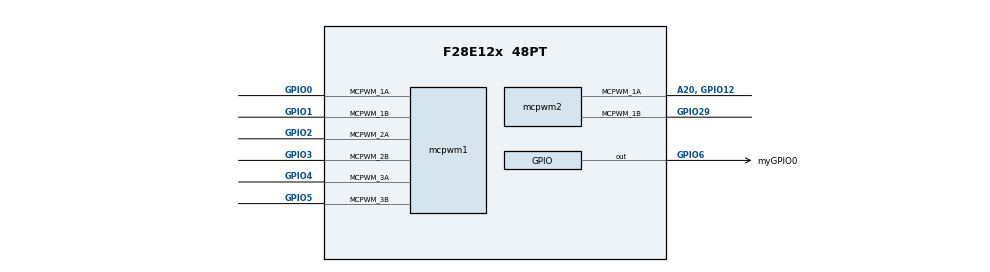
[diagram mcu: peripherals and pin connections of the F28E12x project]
/**
 * @cliArgs --device "F28E12x" --package "48PT" --part "F28E12x_48PT" --context "system" --product "C2000WARE@5.04.00.00"
 * @versions {"tool":"1.21.0+dev"}
 */

/**
 * Import the modules used in this configuration.
 */
const gpio             = scripting.addModule("/driverlib/gpio.js", {}, false);
const gpio1            = gpio.addInstance();
const inputxbar_input  = scripting.addModule("/driverlib/inputxbar_input.js", {}, false);
const inputxbar_input1 = inputxbar_input.addInstance();
const mcpwm            = scripting.addModule("/driverlib/mcpwm.js");
const mcpwm1           = mcpwm.addInstance();
const mcpwm2           = mcpwm.addInstance();
const pwmxbar          = scripting.addModule("/driverlib/pwmxbar.js", {}, false);
const pwmxbar1         = pwmxbar.addInstance();

/**
 * Write custom configuration values to the imported modules.
 */
gpio1.$name           = "myGPIO0";
gpio1.direction       = "GPIO_DIR_MODE_OUT";
gpio1.gpioPin.$assign = "GPIO6";

inputxbar_input1.$name          = "myINPUTXBARINPUT0";
inputxbar_input1.inputxbarInput = "XBAR_INPUT13";
inputxbar_input1.inputxbarGpio  = "GPIO6";

mcpwm.commentOutDefaultCode = true;

mcpwm1.$name                                                       = "myMCPWM0";
mcpwm1.mcpwmTimebase_counterMode                                   = "MCPWM_COUNTER_MODE_UP";
mcpwm1.mcpwmTimebase_period                                        = 15999;
mcpwm1.mcpwmCounterCompare_cmpA                                    = 7999;
mcpwm1.mcpwmCounterCompare_cmpB                                    = 7999;
mcpwm1.mcpwmActionQualifier_MCPWM_AQ_OUTPUT_1A_ON_TIMEBASE_ZERO    = "MCPWM_AQ_OUTPUT_HIGH";
mcpwm1.mcpwmActionQualifier_MCPWM_AQ_OUTPUT_1B_ON_TIMEBASE_ZERO    = "MCPWM_AQ_OUTPUT_HIGH";
mcpwm1.mcpwmActionQualifier_MCPWM_AQ_OUTPUT_1A_ON_TIMEBASE_UP_CMPA = "MCPWM_AQ_OUTPUT_LOW";
mcpwm1.mcpwmActionQualifier_MCPWM_AQ_OUTPUT_1B_ON_TIMEBASE_UP_CMPB = "MCPWM_AQ_OUTPUT_LOW";
mcpwm1.mcpwmActionQualifier_MCPWM_AQ_OUTPUT_2A_ON_TIMEBASE_PERIOD  = "MCPWM_AQ_OUTPUT_LOW";
mcpwm1.mcpwmActionQualifier_MCPWM_AQ_OUTPUT_2B_ON_TIMEBASE_PERIOD  = "MCPWM_AQ_OUTPUT_LOW";
mcpwm1.mcpwmActionQualifier_MCPWM_AQ_OUTPUT_2A_ON_TIMEBASE_UP_CMPA = "MCPWM_AQ_OUTPUT_HIGH";
mcpwm1.mcpwmActionQualifier_MCPWM_AQ_OUTPUT_2B_ON_TIMEBASE_UP_CMPB = "MCPWM_AQ_OUTPUT_HIGH";
mcpwm1.mcpwmActionQualifier_MCPWM_AQ_OUTPUT_3A_ON_TIMEBASE_UP_CMPA = "MCPWM_AQ_OUTPUT_HIGH";
mcpwm1.mcpwmActionQualifier_MCPWM_AQ_OUTPUT_3A_ON_TIMEBASE_UP_CMPB = "MCPWM_AQ_OUTPUT_LOW";
mcpwm1.mcpwmActionQualifier_MCPWM_AQ_OUTPUT_3B_ON_TIMEBASE_UP_CMPA = "MCPWM_AQ_OUTPUT_LOW";
mcpwm1.mcpwmActionQualifier_MCPWM_AQ_OUTPUT_3B_ON_TIMEBASE_UP_CMPB = "MCPWM_AQ_OUTPUT_HIGH";
mcpwm1.mcpwmEventTrigger_enableInterrupt                           = true;
mcpwm1.mcpwmEventTrigger_registerInterrupts                        = true;
mcpwm1.mcpwmCounterCompare_cmpA_pwm2                               = 7999;
mcpwm1.mcpwmCounterCompare_cmpB_pwm2                               = 7999;
mcpwm1.mcpwmCounterCompare_cmpB_pwm3                               = 7999;
mcpwm1.mcpwmEventTrigger_interruptSource                           = ["MCPWM_INT_TZ_CBC"];
mcpwm1.mcpwmTripZone_MCPWM_TZ_ACTION_EVENT_TZA                     = "MCPWM_TZ_ACTION_LOW";
mcpwm1.mcpwmTripZone_MCPWM_TZ_ACTION_EVENT_TZB                     = "MCPWM_TZ_ACTION_HIGH";
mcpwm1.mcpwmTripZone_cbcSource                                     = ["MCPWM_TZ_SIGNAL_CBC1"];
mcpwm1.mcpwmTripZone_cbcPulse                                      = "MCPWM_TZ_CBC_PULSE_CLR_CNTR_ZERO";
mcpwm1.mcpwmTimebase_emulationMode                                 = "MCPWM_EMULATION_FREE_RUN";
mcpwm1.mcpwm.$assign                                               = "MCPWM1";
mcpwm1.mcpwm.mcpwm_1aPin.$assign                                   = "GPIO0";
mcpwm1.mcpwm.mcpwm_1bPin.$assign                                   = "GPIO1";
mcpwm1.mcpwm.mcpwm_2aPin.$assign                                   = "GPIO2";
mcpwm1.mcpwm.mcpwm_2bPin.$assign                                   = "GPIO3";
mcpwm1.mcpwm.mcpwm_3aPin.$assign                                   = "GPIO4";
mcpwm1.mcpwm.mcpwm_3bPin.$assign                                   = "GPIO5";
mcpwm1.mcpwmInt.enableInterrupt                                    = true;

mcpwm2.$name                                                         = "myMCPWM1";
mcpwm2.useCase                                                       = "2CH";
mcpwm2.mcpwmTimebase_counterMode                                     = "MCPWM_COUNTER_MODE_UP_DOWN";
mcpwm2.mcpwmTimebase_period                                          = 8000;
mcpwm2.mcpwmActionQualifier_MCPWM_AQ_OUTPUT_1A_ON_TIMEBASE_UP_CMPA   = "MCPWM_AQ_OUTPUT_HIGH";
mcpwm2.mcpwmActionQualifier_MCPWM_AQ_OUTPUT_1A_ON_TIMEBASE_DOWN_CMPA = "MCPWM_AQ_OUTPUT_LOW";
mcpwm2.mcpwmActionQualifier_MCPWM_AQ_OUTPUT_1B_ON_TIMEBASE_UP_CMPB   = "MCPWM_AQ_OUTPUT_HIGH";
mcpwm2.mcpwmActionQualifier_MCPWM_AQ_OUTPUT_1B_ON_TIMEBASE_DOWN_CMPB = "MCPWM_AQ_OUTPUT_LOW";
mcpwm2.mcpwmEventTrigger_enableInterrupt                             = true;
mcpwm2.mcpwmEventTrigger_registerInterrupts                          = true;
mcpwm2.mcpwmEventTrigger_interruptSource                             = ["MCPWM_INT_TZ_OST"];
mcpwm2.mcpwmTripZone_MCPWM_TZ_ACTION_EVENT_TZA                       = "MCPWM_TZ_ACTION_LOW";
mcpwm2.mcpwmTripZone_MCPWM_TZ_ACTION_EVENT_TZB                       = "MCPWM_TZ_ACTION_HIGH";
mcpwm2.mcpwmTripZone_oneShotSource                                   = ["MCPWM_TZ_SIGNAL_OSHT1"];
mcpwm2.mcpwmTimebase_emulationMode                                   = "MCPWM_EMULATION_FREE_RUN";
mcpwm2.mcpwmCounterCompare_cmpA                                      = 4000;
mcpwm2.mcpwmCounterCompare_cmpB                                      = 4000;
mcpwm2.mcpwm.$assign                                                 = "MCPWM3";
mcpwm2.mcpwm.mcpwm_1aPin.$assign                                     = "A20, GPIO12";
mcpwm2.mcpwm.mcpwm_1bPin.$assign                                     = "GPIO29";
mcpwm2.mcpwmInt.enableInterrupt                                      = true;

pwmxbar1.$name           = "myPWMXBAR0";
pwmxbar1.useSourceSelect = true;
pwmxbar1.sourceSignals   = ["INPUTXBAR_INPUT13"];

/**
 * Pinmux solution for unlocked pins/peripherals. This ensures that minor changes to the automatic solver in a future
 * version of the tool will not impact the pinmux you originally saw.  These lines can be completely deleted in order to
 * re-solve from scratch.
 */
gpio1.gpioPin["GPIO#"].$suggestSolution = "GPIO6";
